# altera_epcq_controller register map
Registers are 32-bit, read-only, reset 0x0 unless marked. A register's access mark holds for its fields unless they carry their own. Offsets are from the block's base; lines under a group give offsets from that group; [hi:lo] are bit positions; {n}, {i} and the like mark numbered series; 'fields as' and 'values as' point back to an identical list; <NAME> marks a mode.

## Memory map
0x00000000 altera_epcq_controller — altera serial flash controller

## altera_epcq_controller — altera serial flash controller
Base 0x00000000
0x00 flash_rd_status — Perform read operation on flash device status register and store the read back data.
0x04 flash_rd_sid — Perform read operation to extract flash device silicon ID and store the read back data. Only support in EPCS16 and EPCS64 flash devices.
0x08 flash_rd_rdid — Perform read operation to extract flash device memory capacity and store the read back data.
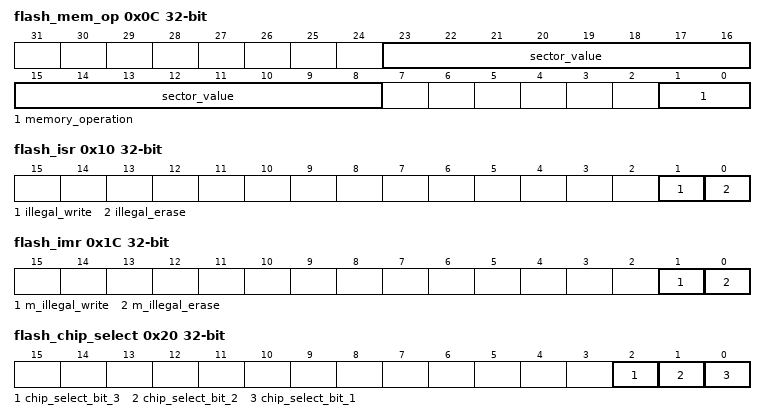
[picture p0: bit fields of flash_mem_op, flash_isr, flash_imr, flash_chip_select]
0x0C flash_mem_op wo — To protect and erase memory
  [23:8] sector_value, [1:0] memory_operation
0x10 flash_isr rw — Interrupt status register
  [1] illegal_write write-1-clears, [0] illegal_erase write-1-clears
0x1C flash_imr rw — To mask of interrupt status register
  [1] m_illegal_write write-1-clears, [0] m_illegal_erase write-1-clears
0x20 flash_chip_select wo — Chip select values
  [2] chip_select_bit_3, [1] chip_select_bit_2, [0] chip_select_bit_1
